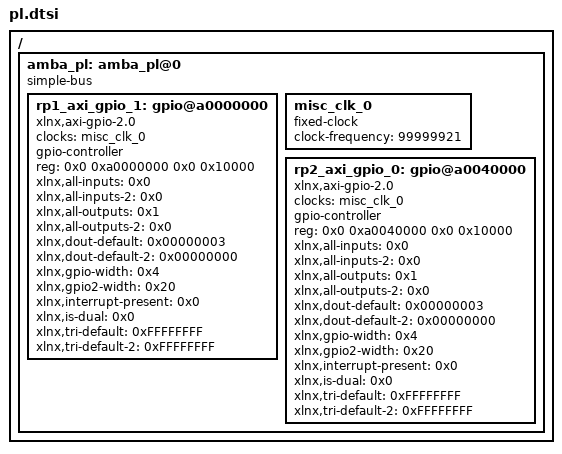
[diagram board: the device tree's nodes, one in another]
/*
 * CAUTION: This file is automatically generated by Xilinx.
 * Version: XSCT 2021.2
 * Today is: Tue Apr 11 14:30:03 2023
 */


/ {
	amba_pl: amba_pl@0 {
		#address-cells = <2>;
		#size-cells = <2>;
		compatible = "simple-bus";
		ranges ;
		rp1_axi_gpio_1: gpio@a0000000 {
			#gpio-cells = <3>;
			clock-names = "s_axi_aclk";
			clocks = <&misc_clk_0>;
			compatible = "xlnx,axi-gpio-2.0", "xlnx,xps-gpio-1.00.a";
			gpio-controller ;
			reg = <0x0 0xa0000000 0x0 0x10000>;
			xlnx,all-inputs = <0x0>;
			xlnx,all-inputs-2 = <0x0>;
			xlnx,all-outputs = <0x1>;
			xlnx,all-outputs-2 = <0x0>;
			xlnx,dout-default = <0x00000003>;
			xlnx,dout-default-2 = <0x00000000>;
			xlnx,gpio-width = <0x4>;
			xlnx,gpio2-width = <0x20>;
			xlnx,interrupt-present = <0x0>;
			xlnx,is-dual = <0x0>;
			xlnx,tri-default = <0xFFFFFFFF>;
			xlnx,tri-default-2 = <0xFFFFFFFF>;
		};
		misc_clk_0: misc_clk_0 {
			#clock-cells = <0>;
			clock-frequency = <99999921>;
			compatible = "fixed-clock";
		};
		rp2_axi_gpio_0: gpio@a0040000 {
			#gpio-cells = <3>;
			clock-names = "s_axi_aclk";
			clocks = <&misc_clk_0>;
			compatible = "xlnx,axi-gpio-2.0", "xlnx,xps-gpio-1.00.a";
			gpio-controller ;
			reg = <0x0 0xa0040000 0x0 0x10000>;
			xlnx,all-inputs = <0x0>;
			xlnx,all-inputs-2 = <0x0>;
			xlnx,all-outputs = <0x1>;
			xlnx,all-outputs-2 = <0x0>;
			xlnx,dout-default = <0x00000003>;
			xlnx,dout-default-2 = <0x00000000>;
			xlnx,gpio-width = <0x4>;
			xlnx,gpio2-width = <0x20>;
			xlnx,interrupt-present = <0x0>;
			xlnx,is-dual = <0x0>;
			xlnx,tri-default = <0xFFFFFFFF>;
			xlnx,tri-default-2 = <0xFFFFFFFF>;
		};
	};
};
